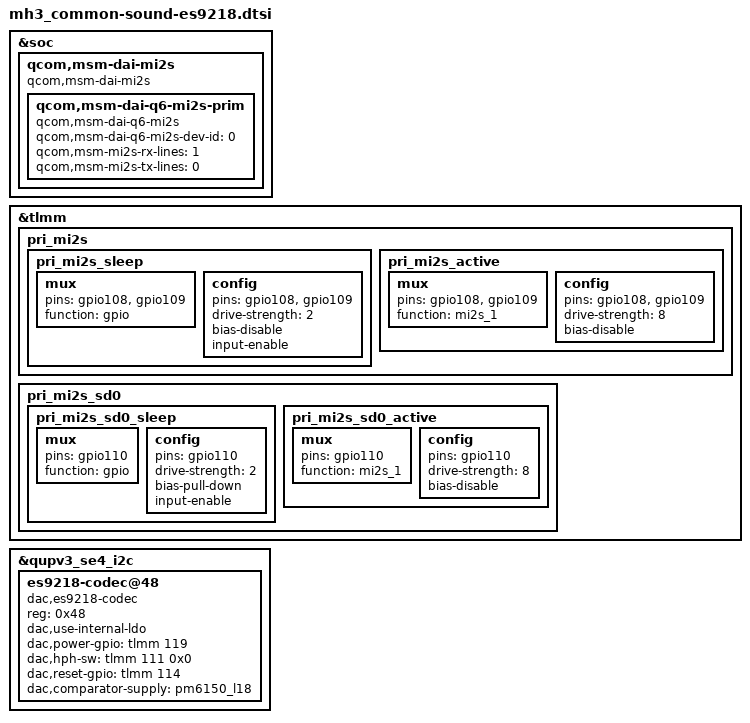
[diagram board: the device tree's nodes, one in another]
/*
 * Copyright (c) 2018, The Linux Foundation. All rights reserved.
 *
 * This program is free software; you can redistribute it and/or modify
 * it under the terms of the GNU General Public License version 2 and
 * only version 2 as published by the Free Software Foundation.
 *
 * This program is distributed in the hope that it will be useful,
 * but WITHOUT ANY WARRANTY; without even the implied warranty of
 * MERCHANTABILITY or FITNESS FOR A PARTICULAR PURPOSE.  See the
 * GNU General Public License for more details.
 */


&soc {
	qcom,msm-dai-mi2s {
		compatible = "qcom,msm-dai-mi2s";

		qcom,msm-dai-q6-mi2s-prim {
                       compatible = "qcom,msm-dai-q6-mi2s";
                       qcom,msm-dai-q6-mi2s-dev-id = <0>;
                       qcom,msm-mi2s-rx-lines = <1>; /* SD0 used as output */
                       qcom,msm-mi2s-tx-lines = <0>;
		};
	};

};

&tlmm {
	pri_mi2s {
		pri_mi2s_sleep: pri_mi2s_sleep {
			mux {
				pins = "gpio108", "gpio109";
				function = "gpio";
			};

			config {
				pins = "gpio108", "gpio109";
				drive-strength = <2>;   /* 2 mA */
				bias-disable;         /* NO PULL */
				input-enable;
			};
		};

		pri_mi2s_active: pri_mi2s_active {
			mux {
				pins = "gpio108", "gpio109";
				function = "mi2s_1";
			};

			config {
				pins = "gpio108", "gpio109";
				drive-strength = <8>;   /* 8 mA */
				bias-disable;           /* NO PULL */
			};
		};
	};

	pri_mi2s_sd0 {
		pri_mi2s_sd0_sleep: pri_mi2s_sd0_sleep {
			mux {
				pins = "gpio110";
				function = "gpio";
			};

			config {
				pins = "gpio110";
				drive-strength = <2>;   /* 2 mA */
				bias-pull-down;         /* PULL DOWN */
				input-enable;
			};
		};

		pri_mi2s_sd0_active: pri_mi2s_sd0_active {
			mux {
				pins = "gpio110";
				function = "mi2s_1";
			};

			config {
				pins = "gpio110";
				drive-strength = <8>;   /* 8 mA */
				bias-disable;           /* NO PULL */
			};
		};
	};
};

&qupv3_se4_i2c { /* QUPV3 SE4  */
	status = "ok";
	es9218-codec@48{
		compatible = "dac,es9218-codec";
		status = "ok";
		reg = <0x48>;
		dac,use-internal-ldo;
		dac,power-gpio = <&tlmm 119 0x0>;
		dac,hph-sw = <&tlmm 111 0x0>;
		dac,reset-gpio = <&tlmm 114 0x0>;
		dac,comparator-supply = <&pm6150_l18>;
	};
};
